# PIC32MK0512GPH048 register map
Vendor: Microchip
Registers are 32-bit, read-write, reset 0x0 unless marked. A register's access mark holds for its fields unless they carry their own. Addresses are absolute, and some are shared; only a register's first bit layout is shown; [hi:lo] are bit positions; {n}, {i} and the like mark numbered series; 'fields as' and 'values as' point back to an identical list.

## PORTG
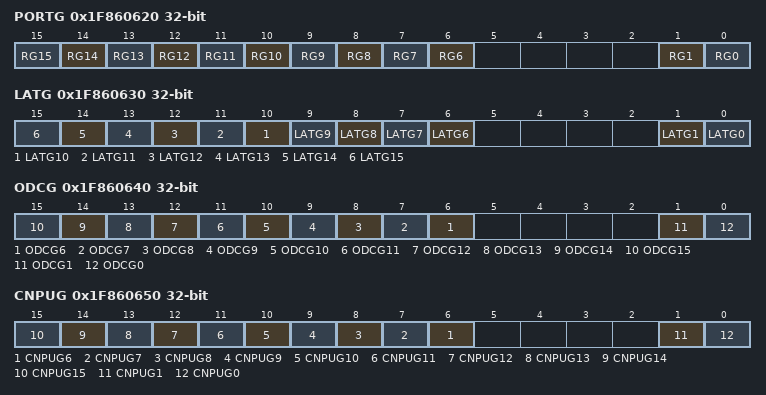
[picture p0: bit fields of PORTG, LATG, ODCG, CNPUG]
0x1F860620 PORTG reset not defined — (power-on value ----------------xxxxxxxxxx----xx)
  [n] RG{n} (n=6..15), [1] RG1, [0] RG0
0x1F860630 LATG reset not defined — (power-on value ----------------xxxxxxxxxx----xx)
  [n] LATG{n} (n=6..15), [1] LATG1, [0] LATG0
0x1F860640 ODCG
  [n] ODCG{n} (n=6..15), [1] ODCG1, [0] ODCG0
0x1F860650 CNPUG
  [n] CNPUG{n} (n=6..15), [1] CNPUG1, [0] CNPUG0
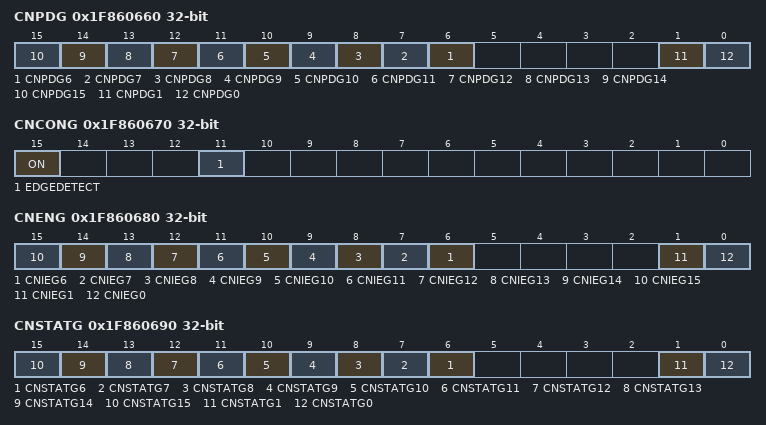
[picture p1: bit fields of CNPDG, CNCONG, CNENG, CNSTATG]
0x1F860660 CNPDG
  [n] CNPDG{n} (n=6..15), [1] CNPDG1, [0] CNPDG0
0x1F860670 CNCONG
  [15] ON, [11] EDGEDETECT
0x1F860680 CNENG
  [n] CNIEG{n} (n=6..15), [1] CNIEG1, [0] CNIEG0
0x1F860690 CNSTATG
  [n] CNSTATG{n} (n=6..15), [1] CNSTATG1, [0] CNSTATG0
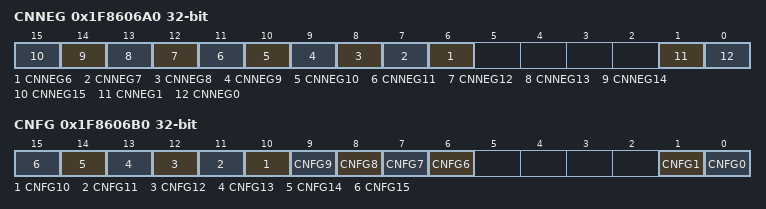
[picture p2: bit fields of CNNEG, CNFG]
0x1F8606A0 CNNEG
  [n] CNNEG{n} (n=6..15), [1] CNNEG1, [0] CNNEG0
0x1F8606B0 CNFG
  [n] CNFG{n} (n=6..15), [1] CNFG1, [0] CNFG0

## adc_sar_ctrl_upb
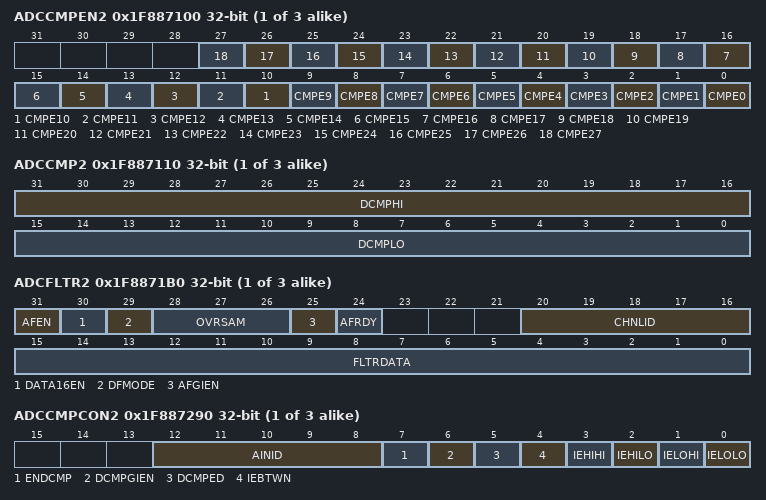
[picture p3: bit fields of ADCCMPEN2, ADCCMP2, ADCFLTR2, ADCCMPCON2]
{0x1F8870C0+0x20*i} ADCCMPEN{i} (i=2..4)
  [n] CMPE{n} (n=0..27)
{0x1F8870D0+0x20*i} ADCCMP{i} (i=2..4)
  [31:16] DCMPHI, [15:0] DCMPLO
{0x1F887190+0x10*i} ADCFLTR{i} (i=2..4)
  [31] AFEN, [30] DATA16EN, [29] DFMODE, [28:26] OVRSAM, [25] AFGIEN, [24] AFRDY ro, [20:16] CHNLID, [15:0] FLTRDATA ro
{0x1F887270+0x10*i} ADCCMPCON{i} (i=2..4)
  [12:8] AINID ro, [7] ENDCMP, [6] DCMPGIEN, [5] DCMPED ro, [4] IEBTWN, [3] IEHIHI, [2] IEHILO, [1] IELOHI, [0] IELOLO
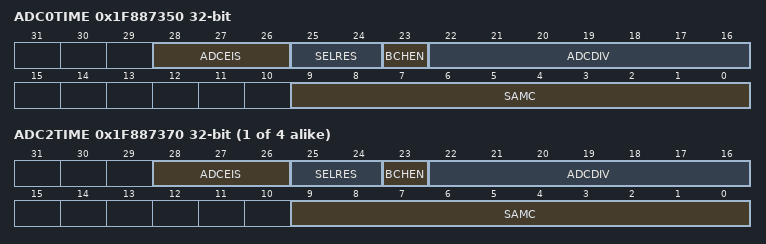
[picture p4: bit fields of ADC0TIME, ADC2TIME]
0x1F887350 ADC0TIME reset not defined — (power-on value ---00000x0000000------0000000000)
  [28:26] ADCEIS, [25:24] SELRES, [23] BCHEN, [22:16] ADCDIV, [9:0] SAMC
{0x1F887350+0x10*i} ADC{i}TIME reset not defined (i=2..5) — (power-on value ---00000x0000000------0000000000)
  fields as ADC0TIME

## RTCC
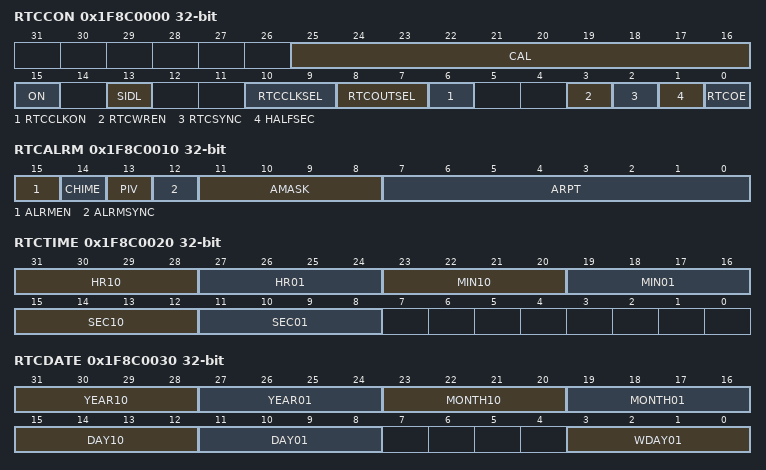
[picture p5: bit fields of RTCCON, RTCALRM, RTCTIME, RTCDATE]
0x1F8C0000 RTCCON
  [25:16] CAL, [15] ON, [13] SIDL, [10:9] RTCCLKSEL, [8:7] RTCOUTSEL, [6] RTCCLKON, [3] RTCWREN, [2] RTCSYNC ro, [1] HALFSEC ro, [0] RTCOE
0x1F8C0010 RTCALRM
  [15] ALRMEN, [14] CHIME, [13] PIV, [12] ALRMSYNC, [11:8] AMASK, [7:0] ARPT
0x1F8C0020 RTCTIME reset not defined — (power-on value 000xxxxxxxxxxxxx0xxxxxxx--------)
  [31:28] HR10, [27:24] HR01, [23:20] MIN10, [19:16] MIN01, [15:12] SEC10, [11:8] SEC01
0x1F8C0030 RTCDATE reset not defined — (power-on value xxxxxxxx000xxxxx00xxxxxx----0xxx)
  [31:28] YEAR10, [27:24] YEAR01, [23:20] MONTH10, [19:16] MONTH01, [15:12] DAY10, [11:8] DAY01, [3:0] WDAY01
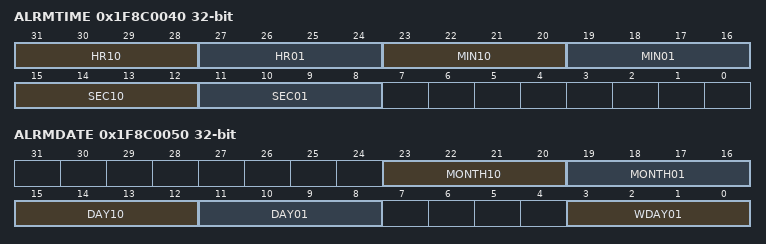
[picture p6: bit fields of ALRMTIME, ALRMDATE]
0x1F8C0040 ALRMTIME reset not defined — (power-on value 000xxxxx0xxxxxxx0xxxxxxx--------)
  fields as RTCTIME
0x1F8C0050 ALRMDATE reset not defined — (power-on value --------000xxxxx00xxxxxx----0xxx)
  [23:20] MONTH10, [19:16] MONTH01, [15:12] DAY10, [11:8] DAY01, [3:0] WDAY01

## lpwr_deep_sleep_ctrl
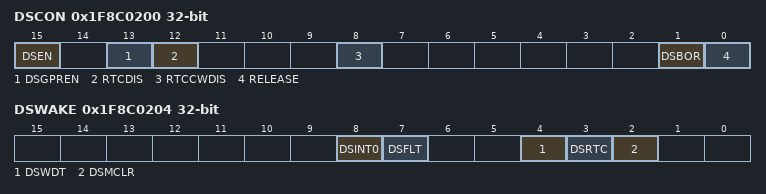
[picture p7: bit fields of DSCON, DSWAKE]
0x1F8C0200 DSCON
  [15] DSEN, [13] DSGPREN, [12] RTCDIS, [8] RTCCWDIS, [1] DSBOR, [0] RELEASE
0x1F8C0204 DSWAKE
  [8] DSINT0, [7] DSFLT, [4] DSWDT, [3] DSRTC, [2] DSMCLR
0x1F8C0208 DSGPR0
  [31:0] DSGPR
{0x1F8C020C+4i} DSGPR{i} (i=1..32)
  [31:0] DSGPR

## SB
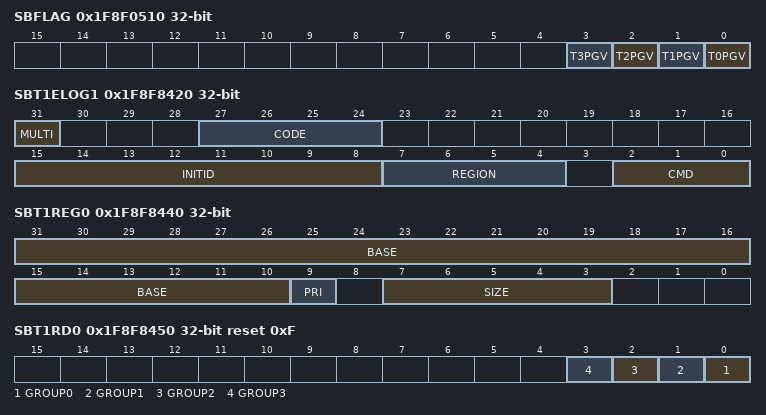
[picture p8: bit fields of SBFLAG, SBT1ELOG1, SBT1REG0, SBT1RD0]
0x1F8F0510 SBFLAG ro
  [n] T{n}PGV (n=0..3)
0x1F8F8420 SBT1ELOG1
  [31] MULTI, [27:24] CODE, [15:8] INITID ro, [7:4] REGION ro, [2:0] CMD ro
0x1F8F8424 SBT1ELOG2 ro
  [1:0] GROUP
0x1F8F8428 SBT1ECON
  [24] ERRP
0x1F8F8430 SBT1ECLRS ro
  [0] CLEAR
0x1F8F8438 SBT1ECLRM ro
  [0] CLEAR
0x1F8F8440 SBT1REG0 reset not defined — (power-on value 0000000000000000000000x-00000---)
  [31:10] BASE, [9] PRI ro, [7:3] SIZE
0x1F8F8450 SBT1RD0 reset 0xF
  [n] GROUP{n} (n=0..3)
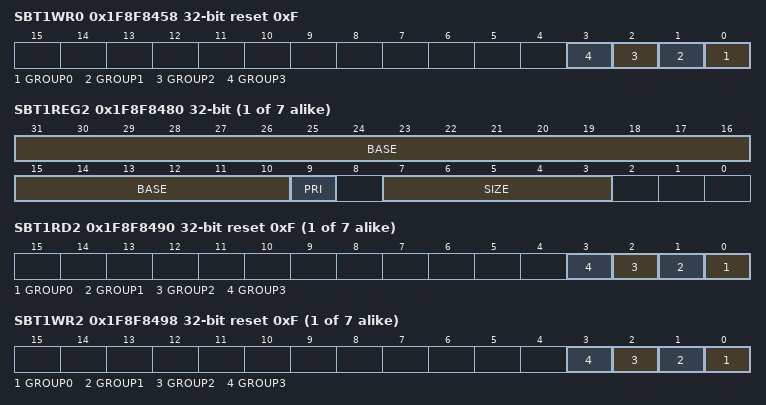
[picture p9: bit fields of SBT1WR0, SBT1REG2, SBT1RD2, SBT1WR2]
0x1F8F8458 SBT1WR0 reset 0xF
  [n] GROUP{n} (n=0..3)
{0x1F8F8440+0x20*i} SBT1REG{i} reset not defined (i=2..8) — (power-on value 0000000000000000000000x-00000---)
  [31:10] BASE, [9] PRI ro, [7:3] SIZE
{0x1F8F8450+0x20*i} SBT1RD{i} reset 0xF (i=2..8)
  [n] GROUP{n} (n=0..3)
{0x1F8F8458+0x20*i} SBT1WR{i} reset 0xF (i=2..8)
  [n] GROUP{n} (n=0..3)

## DOS_EIP_00136_ssx
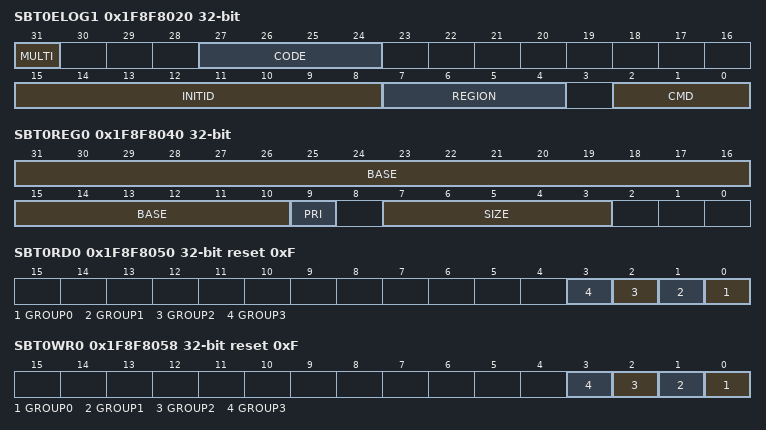
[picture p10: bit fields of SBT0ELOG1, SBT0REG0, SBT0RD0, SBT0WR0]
0x1F8F8020 SBT0ELOG1
  [31] MULTI, [27:24] CODE, [15:8] INITID ro, [7:4] REGION ro, [2:0] CMD ro
0x1F8F8024 SBT0ELOG2 ro
  [1:0] GROUP
0x1F8F8028 SBT0ECON
  [24] ERRP
0x1F8F8030 SBT0ECLRS ro
  [0] CLEAR
0x1F8F8038 SBT0ECLRM ro
  [0] CLEAR
0x1F8F8040 SBT0REG0 reset not defined — (power-on value 0000000000000000000000x-00000---)
  [31:10] BASE, [9] PRI ro, [7:3] SIZE
0x1F8F8050 SBT0RD0 reset 0xF
  [n] GROUP{n} (n=0..3)
0x1F8F8058 SBT0WR0 reset 0xF
  [n] GROUP{n} (n=0..3)
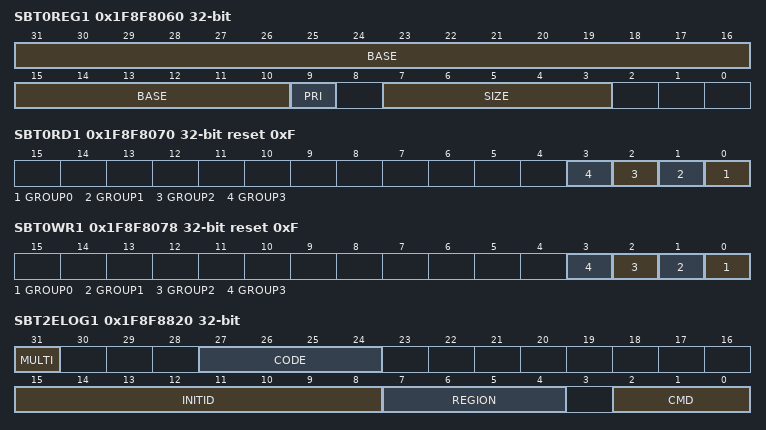
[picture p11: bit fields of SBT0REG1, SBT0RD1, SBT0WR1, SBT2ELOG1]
0x1F8F8060 SBT0REG1 reset not defined — (power-on value 0000000000000000000000x-00000---)
  [31:10] BASE, [9] PRI ro, [7:3] SIZE
0x1F8F8070 SBT0RD1 reset 0xF
  [n] GROUP{n} (n=0..3)
0x1F8F8078 SBT0WR1 reset 0xF
  [n] GROUP{n} (n=0..3)
0x1F8F8820 SBT2ELOG1
  fields as SBT0ELOG1
0x1F8F8824 SBT2ELOG2 ro
  [1:0] GROUP
0x1F8F8828 SBT2ECON
  [24] ERRP
0x1F8F8830 SBT2ECLRS ro
  [0] CLEAR
0x1F8F8838 SBT2ECLRM ro
  [0] CLEAR
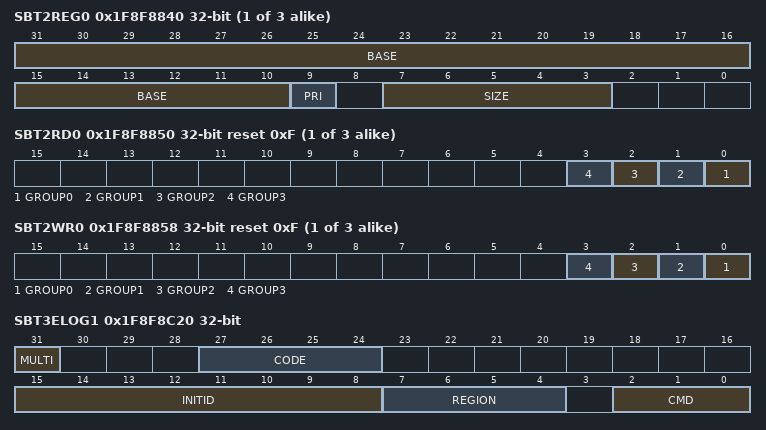
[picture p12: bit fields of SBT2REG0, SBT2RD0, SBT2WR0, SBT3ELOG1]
{0x1F8F8840+0x20*i} SBT2REG{i} reset not defined (i=0..2) — (power-on value 0000000000000000000000x-00000---)
  [31:10] BASE, [9] PRI ro, [7:3] SIZE
{0x1F8F8850+0x20*i} SBT2RD{i} reset 0xF (i=0..2)
  [n] GROUP{n} (n=0..3)
{0x1F8F8858+0x20*i} SBT2WR{i} reset 0xF (i=0..2)
  [n] GROUP{n} (n=0..3)
0x1F8F8C20 SBT3ELOG1
  fields as SBT0ELOG1
0x1F8F8C24 SBT3ELOG2 ro
  [1:0] GROUP
0x1F8F8C28 SBT3ECON
  [24] ERRP
0x1F8F8C30 SBT3ECLRS ro
  [0] CLEAR
0x1F8F8C38 SBT3ECLRM ro
  [0] CLEAR
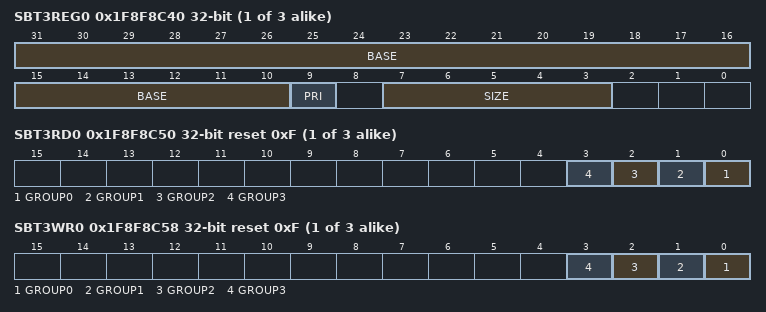
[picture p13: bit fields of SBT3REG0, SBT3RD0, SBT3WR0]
{0x1F8F8C40+0x20*i} SBT3REG{i} reset not defined (i=0..2) — (power-on value 0000000000000000000000x-00000---)
  [31:10] BASE, [9] PRI ro, [7:3] SIZE
{0x1F8F8C50+0x20*i} SBT3RD{i} reset 0xF (i=0..2)
  [n] GROUP{n} (n=0..3)
{0x1F8F8C58+0x20*i} SBT3WR{i} reset 0xF (i=0..2)
  [n] GROUP{n} (n=0..3)
